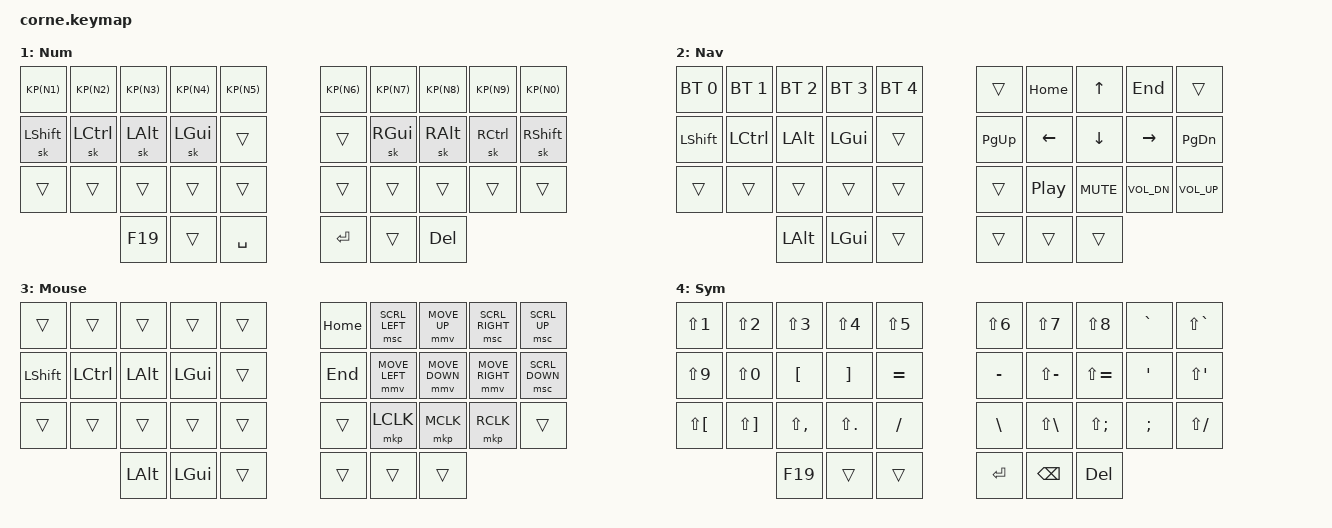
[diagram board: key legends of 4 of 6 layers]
/*
 * Copyright (c) 2020 The ZMK Contributors
 *
 * SPDX-License-Identifier: MIT
 */

#include <behaviors.dtsi>
#include <dt-bindings/zmk/keys.h>
#include <dt-bindings/zmk/bt.h>
#include <dt-bindings/zmk/pointing.h>


#define KP(keycode) &as_kp LS(keycode) keycode

/* 
 * 5-column Corne assumed positions:
 *
 * Left alpha:   0 1 2 3 4    10 11 12 13 14    20 21 22 23 24
 * Right alpha:  5 6 7 8 9    15 16 17 18 19    25 26 27 28 29
 * Thumbs:       30 31 32     33 34 35
 */

#define HRML(k1, k2, k3, k4) &lhm LSHFT k1 &lhm LCTRL k2 &lhm LALT k3 &lhm LGUI k4
#define HRMR(k1, k2, k3, k4) &rhm RGUI k1 &rhm RALT k2 &rhm RCTRL k3 &rhm RSHFT k4

/ {
    chosen {
        zmk,physical-layout = &foostan_corne_5col_layout;
    };

    combos {
        compatible = "zmk,combos";
        timeout-ms = <30>;
        require-prior-idle-ms = <150>;

        combo_copy {
            bindings = <&kp LG(C)>;
            key-positions = <21 22>;
        };

        combo_paste {
            bindings = <&kp LG(V)>;
            key-positions = <22 23>;
        };

        combo_cut {
            bindings = <&kp LG(X)>;
            key-positions = <21 23>;
        };

        combo_select_all {
            bindings = <&kp LG(A)>;
            key-positions = <10 11>;
        };

        combo_zx_undo {
            bindings = <&kp LG(Z)>;
            key-positions = <20 21>;
        };

        combo_zxc_redo {
            bindings = <&kp LG(LS(Z))>;
            key-positions = <20 21 22>;
        };

        combo_hyper {
            bindings = <&sk LC(LA(LS(LGUI)))>;
            key-positions = <12 13>;
        };

        combo_meh {
            bindings = <&sk LC(LA(LSHFT))>;
            key-positions = <16 17>;
        };


        combo_we_escape {
            bindings = <&kp ESCAPE>;
            key-positions = <1 2>;
        };

        combo_sd_tab {
            bindings = <&kp TAB>;
            key-positions = <11 12>;
        };

        combo_asd_caps {
            bindings = <&kp CAPSLOCK>;
            key-positions = <10 11 12>;
        };

        /*
        combo_qw_grave_tilde {
            bindings = <KP(GRAVE)>;
            key-positions = <0 1>;
        };
        */



        combo_io_bspc {
            bindings = <&kp BACKSPACE>;
            key-positions = <7 8>;
        };

        combo_kl_return {
            bindings = <&kp RETURN>;
            key-positions = <17 18>;
        };

        /*
        combo_uio_excl {
            bindings = <KP(EQUAL)>;
            key-positions = <6 7 8>;
            slow-release;
        };

        combo_jkl_minus_under {
            bindings = <KP(MINUS)>;
            key-positions = <16 17 18>;
            slow-release;
        };
        */


    };

    macros {
        sel_copy: sel_copy {
            compatible = "zmk,behavior-macro";
            #binding-cells = <0>;
            bindings = <&kp LG(A)>, <&kp LG(C)>;
        };
        
        sel_cut: sel_cut {
            compatible = "zmk,behavior-macro";
            #binding-cells = <0>;
            bindings = <&kp LG(A)>, <&kp LG(X)>;
        };
    };

    behaviors {
        as_kp: auto_shift_key_press {
            compatible = "zmk,behavior-hold-tap";
            #binding-cells = <2>;
            tapping-term-ms = <220>;
            quick-tap-ms = <150>;
            flavor = "tap-preferred";
            bindings = <&kp>, <&kp>;
        };

        /*
         * Left-hand home-row mods.
         * Hold only triggers when combined with right-hand keys.
         */
        lhm: left_home_row_mods {
            compatible = "zmk,behavior-hold-tap";
            #binding-cells = <2>;
            tapping-term-ms = <220>;
            quick-tap-ms = <150>;
            require-prior-idle-ms = <150>;
            flavor = "balanced";
            hold-trigger-key-positions = <5 6 7 8 9 15 16 17 18 19 25 26 27 28 29 33 34 35>;
            hold-trigger-on-release;
            bindings = <&kp>, <&kp>;
        };

        /*
         * Right-hand home-row mods.
         * Hold only triggers when combined with left-hand keys.
         */
        rhm: right_home_row_mods {
            compatible = "zmk,behavior-hold-tap";
            #binding-cells = <2>;
            tapping-term-ms = <220>;
            quick-tap-ms = <150>;
            require-prior-idle-ms = <150>;
            flavor = "balanced";
            hold-trigger-key-positions = <0 1 2 3 4 10 11 12 13 14 20 21 22 23 24 30 31 32>;
            hold-trigger-on-release;
            bindings = <&kp>, <&kp>;
        };
    };
        keymap {
                compatible = "zmk,keymap";

        default_layer {
// -----------------------------------------------------------------------------------------
// |  Q  |  W  |  E  |  R  |  T  |     |  Y  |  U   |  I   |  O   | P |
// |  A  |  S  |  D  |  F  |  G  |     |  H  |  J   |  K   |  L   | ' | 
// |  Z  |  X  |  C  |  V  |  B  |     |  N  |  M   | , | . | / |
//            | GLOBE | Esc/Fun | Space/Sym |    | Num | Nav | Mouse |
            display-name = "Base";
            bindings = <
                &kp Q &kp W &kp E &kp R &kp T     &kp Y &kp U &kp I &kp O &kp P
                HRML(A, S, D, F) &kp G            &kp H HRMR(J, K, L, SQT)
                &kp Z &kp X &kp C &kp V &kp B     &kp N &kp M &kp COMMA &kp DOT &kp FSLH
                &kp F19    &lt 5 ESCAPE  &lt 4 SPACE    &lt 1 RETURN  &lt 2 BACKSPACE  &lt 3 DELETE
            >;
        };
                
        num_layer {
// -----------------------------------------------------------------------------------------
// | 1/! | 2/@ | 3/# | 4/$ | 5/% |     | 6/^ | 7/& | 8/* | 9/( | 0/) |
// | SHFT| CTRL| ALT | GUI |     |     |     | GUI | ALT | CTRL | SHFT|
// |     |     |     |     |     |     |     |     |     |     |     |
//             | GLOBE |     | SPACE |     | RET |     | DEL |
            display-name = "Num";
            bindings = <
                KP(N1) KP(N2) KP(N3) KP(N4) KP(N5)     KP(N6) KP(N7) KP(N8) KP(N9) KP(N0)
                &sk LSHFT &sk LCTRL &sk LALT &sk LGUI &trans     &trans &sk RGUI &sk RALT &sk RCTRL &sk RSHFT
                &trans &trans &trans &trans &trans               &trans &trans &trans &trans &trans
                &kp F19    &trans  &kp SPACE                     &kp RETURN  &trans  &kp DELETE
            >;
        };

        nav_layer {
// -----------------------------------------------------------------------------------------
    // | BT0 | BT1 | BT2 | BT3 | BT4  |     |      |   Home   |  UP |  End    |   |
    // | SHFT| CTRL| ALT | GUI |      |     |  Page Up   | Left  | Down | Right| Page Down  |
    // |     |     |     |     |      |     |      | Play | Mute | Vol- | Vol+ |
//             |  ALT   | CMD    |  SPACE    |     |       |      |      |
            display-name = "Nav";
            bindings = <
    &bt BT_SEL 0 &bt BT_SEL 1 &bt BT_SEL 2 &bt BT_SEL 3 &bt BT_SEL 4     &trans &kp HOME &kp UP &kp END &trans
     &kp LSHFT &kp LCTRL &kp LALT &kp LGUI &trans     &kp PG_UP &kp LEFT &kp DOWN &kp RIGHT &kp PG_DN
       &trans &trans &trans &trans &trans     &trans &kp C_PP &kp C_MUTE &kp C_VOL_DN &kp C_VOL_UP
    &kp LALT &kp LGUI &trans    &trans &trans &trans
            >;
        };

        mouse_layer { 
// -----------------------------------------------------------------------------------------
// |     |     |     |     |      |     | Home | S<-   |  ^   | S-> | S^   |
// | SHFT| CTRL| ALT | GUI |      |     | End  | <-    |  v   | ->  | Sv   |
// |     |     |     |     |      |     |      | LCLK  | MCLK | RCLK|      |
//             |     |     |      |     |      |      |      |
            display-name = "Mouse";
            bindings = <
   &trans &trans &trans &trans &trans     &kp HOME &msc SCRL_LEFT &mmv MOVE_UP &msc SCRL_RIGHT &msc SCRL_UP
    &kp LSHFT &kp LCTRL &kp LALT &kp LGUI &trans     &kp END &mmv MOVE_LEFT &mmv MOVE_DOWN &mmv MOVE_RIGHT &msc SCRL_DOWN
    &trans &trans &trans &trans &trans     &trans &mkp LCLK &mkp MCLK &mkp RCLK &trans
    &kp LALT &kp LGUI &trans    &trans &trans &trans
            >;
        };

        sym_layer {
// -----------------------------------------------------------------------------------------
// |  !  |  @  |  #  |  $  |  %  |     |  ^  |  &  |  *  |  `  |  ~  |
// |  (  |  )  |  [  |  ]  |  =  |     |  -  |  _  |  +  |  '  |  "  |
// |  {  |  }  |  <  |  >  |  /  |     |  \  |  |  |  :  |  ;  |  ?  |
            display-name = "Sym";
            bindings = <
                &kp LS(N1)     &kp LS(N2)     &kp LS(N3)     &kp LS(N4)     &kp LS(N5)          &kp LS(N6)     &kp LS(N7)     &kp LS(N8)     &kp GRAVE       &kp LS(GRAVE)
                &kp LS(N9)     &kp LS(N0)     &kp LBKT       &kp RBKT       &kp EQUAL           &kp MINUS      &kp LS(MINUS)  &kp LS(EQUAL)  &kp SQT         &kp LS(SQT)
                &kp LS(LBKT)   &kp LS(RBKT)   &kp LS(COMMA)  &kp LS(DOT)    &kp FSLH            &kp BSLH       &kp LS(BSLH)   &kp LS(SEMI)   &kp SEMI        &kp LS(FSLH)
                &kp F19        &trans         &trans                            &kp RETURN     &kp BACKSPACE  &kp DELETE
            >;
        };


        hotkey_layer {
            display-name = "Mods";
            bindings = <
                &kp LG(LS(N1))   &kp LG(LS(N2))     &kp LG(LS(N3))    &kp LG(LS(N4)) &kp LG(LS(N5))    &trans &trans &trans &trans &trans
                &kp LC(LA(LEFT)) &kp LC(LA(RETURN)) &kp LC(LA(RIGHT)) &kp LG(W)      &kp LG(LS(T))     &trans &trans &trans &trans &trans
                &kp LG(BSPC)     &sel_cut           &sel_copy         &kp LG(LC(LS(V))) &kp LG(LBKT)   &trans &trans &trans &trans &trans
                &kp F19          &kp ESCAPE         &kp SPACE                                          &kp RETURN  &kp BACKSPACE  &kp DELETE
            >;
        };
                
                
    };
};








